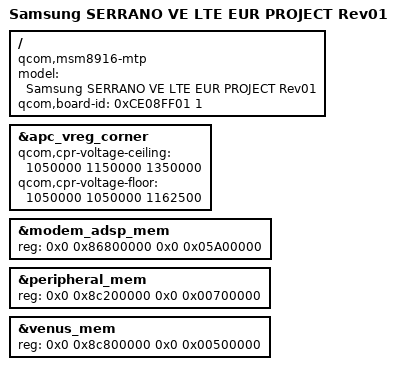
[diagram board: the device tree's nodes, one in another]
/* Copyright (c) 2014, The Linux Foundation. All rights reserved.
*
* This program is free software; you can redistribute it and/or modify
* it under the terms of the GNU General Public License version 2 and
* only version 2 as published by the Free Software Foundation.
*
* This program is distributed in the hope that it will be useful,
* but WITHOUT ANY WARRANTY; without even the implied warranty of
* MERCHANTABILITY or FITNESS FOR A PARTICULAR PURPOSE.  See the
* GNU General Public License for more details.
*/

/dts-v1/;

#include "msm8916-sec-serranovelte-eur-r01.dtsi"
#include "msm8916-memory.dtsi"

/ {
	model = "Samsung SERRANO VE LTE EUR PROJECT Rev01";
	compatible = "qcom,msm8916-mtp", "qcom,msm8916", "qcom,mtp";
	/*QCOM BOARD REV TYPE...*/
        /*qcom,board-id = <8 0>;*/
        /*SEC BOARD REV TYPE...*/
	qcom,board-id = <0xCE08FF01 1>;
        /*parm1)[31:20]platform_id [19:12]qc_hw_id [11:4]national code [3:0] operator, param2)SEC hw-rev*/
};

/* overwrite s2 cpr voltage for model variant */
&apc_vreg_corner {
	qcom,cpr-voltage-ceiling = <1050000 1150000 1350000>;
	qcom,cpr-voltage-floor = <1050000 1050000 1162500>;
};

&modem_adsp_mem {
       reg = <0x0 0x86800000 0x0 0x05A00000>;
};

&peripheral_mem {
       reg = <0x0 0x8c200000 0x0 0x00700000>;
};

&venus_mem {
       reg = <0x0 0x8c800000 0x0 0x00500000>;
};
